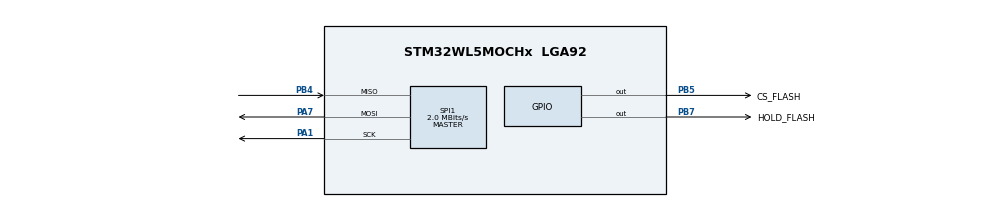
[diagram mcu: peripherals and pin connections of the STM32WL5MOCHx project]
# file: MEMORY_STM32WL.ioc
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Mcu.Family=STM32WL
Mcu.Name=STM32WL5MOCHx
Mcu.Package=LGA92
NVIC.PriorityGroup=NVIC_PRIORITYGROUP_4
PA1.Mode=Full_Duplex_Master
PA1.Signal=SPI1_SCK
PA7.Mode=Full_Duplex_Master
PA7.Signal=SPI1_MOSI
PB4.Mode=Full_Duplex_Master
PB4.Signal=SPI1_MISO
PB5.GPIO_Label=CS_FLASH
PB5.PinState=GPIO_PIN_SET
PB5.Signal=GPIO_Output
PB7.GPIO_Label=HOLD_FLASH
PB7.PinState=GPIO_PIN_SET
PB7.Signal=GPIO_Output
ProjectManager.HeapSize=0x200
ProjectManager.StackSize=0x400
ProjectManager.TargetToolchain=STM32CubeIDE
RCC.HSE_VALUE=32000000
RCC.HSI_VALUE=16000000
RCC.LSE_VALUE=32768
RCC.VCOOutputFreq_Value=32000000
SPI1.CalculateBaudRate=2.0 MBits/s
SPI1.DataSize=SPI_DATASIZE_8BIT
SPI1.Direction=SPI_DIRECTION_2LINES
SPI1.Mode=SPI_MODE_MASTER
SPI1.NSSPMode=SPI_NSS_PULSE_DISABLE
SPI1.VirtualType=VM_MASTER
board=custom

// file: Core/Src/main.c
/* USER CODE BEGIN Header */
/**
 ******************************************************************************
 * @file           : main.c
 * @brief          : Main program body
 ******************************************************************************
 * @attention
 *
 * Copyright (c) 2026 STMicroelectronics.
 * All rights reserved.
 *
 * This software is licensed under terms that can be found in the LICENSE file
 * in the root directory of this software component.
 * If no LICENSE file comes with this software, it is provided AS-IS.
 *
 ******************************************************************************
 */
/* USER CODE END Header */
#include "main.h"

/* USER CODE BEGIN Includes */
#include "MX25L4x/MX25L4x.h"

/* USER CODE END Includes */

SPI_HandleTypeDef hspi1;

/* USER CODE BEGIN PV */
uint32_t memID;
uint8_t pData[50];
/* USER CODE END PV */

void SystemClock_Config(void);
static void MX_GPIO_Init(void);
static void MX_SPI1_Init(void);

int main(void)
{

	/* MCU Configuration--------------------------------------------------------*/

	/* Reset of all peripherals, Initializes the Flash interface and the Systick. */
	HAL_Init();

	/* Configure the system clock */
	SystemClock_Config();

	/* Initialize all configured peripherals */
	MX_GPIO_Init();
	MX_SPI1_Init();
	/* USER CODE BEGIN 2 */

	MX25L4_Init();

	/* USER CODE END 2 */

	/* Infinite loop */
	while (1)
	{

	}
}

void SystemClock_Config(void)
{
	RCC_OscInitTypeDef RCC_OscInitStruct =
	{ 0 };
	RCC_ClkInitTypeDef RCC_ClkInitStruct =
	{ 0 };

	/** Configure the main internal regulator output voltage
	 */
	__HAL_PWR_VOLTAGESCALING_CONFIG(PWR_REGULATOR_VOLTAGE_SCALE2);

	/** Initializes the CPU, AHB and APB buses clocks
	 */
	RCC_OscInitStruct.OscillatorType = RCC_OSCILLATORTYPE_MSI;
	RCC_OscInitStruct.MSIState = RCC_MSI_ON;
	RCC_OscInitStruct.MSICalibrationValue = RCC_MSICALIBRATION_DEFAULT;
	RCC_OscInitStruct.MSIClockRange = RCC_MSIRANGE_6;
	RCC_OscInitStruct.PLL.PLLState = RCC_PLL_NONE;
	if (HAL_RCC_OscConfig(&RCC_OscInitStruct) != HAL_OK)
	{
		Error_Handler();
	}

	/** Configure the SYSCLKSource, HCLK, PCLK1 and PCLK2 clocks dividers
	 */
	RCC_ClkInitStruct.ClockType = RCC_CLOCKTYPE_HCLK3 | RCC_CLOCKTYPE_HCLK | RCC_CLOCKTYPE_SYSCLK | RCC_CLOCKTYPE_PCLK1
			| RCC_CLOCKTYPE_PCLK2;
	RCC_ClkInitStruct.SYSCLKSource = RCC_SYSCLKSOURCE_MSI;
	RCC_ClkInitStruct.AHBCLKDivider = RCC_SYSCLK_DIV1;
	RCC_ClkInitStruct.APB1CLKDivider = RCC_HCLK_DIV1;
	RCC_ClkInitStruct.APB2CLKDivider = RCC_HCLK_DIV1;
	RCC_ClkInitStruct.AHBCLK3Divider = RCC_SYSCLK_DIV1;

	if (HAL_RCC_ClockConfig(&RCC_ClkInitStruct, FLASH_LATENCY_0) != HAL_OK)
	{
		Error_Handler();
	}
}

static void MX_SPI1_Init(void)
{

	/* SPI1 parameter configuration*/
	hspi1.Instance = SPI1;
	hspi1.Init.Mode = SPI_MODE_MASTER;
	hspi1.Init.Direction = SPI_DIRECTION_2LINES;
	hspi1.Init.DataSize = SPI_DATASIZE_8BIT;
	hspi1.Init.CLKPolarity = SPI_POLARITY_LOW;
	hspi1.Init.CLKPhase = SPI_PHASE_1EDGE;
	hspi1.Init.NSS = SPI_NSS_SOFT;
	hspi1.Init.BaudRatePrescaler = SPI_BAUDRATEPRESCALER_2;
	hspi1.Init.FirstBit = SPI_FIRSTBIT_MSB;
	hspi1.Init.TIMode = SPI_TIMODE_DISABLE;
	hspi1.Init.CRCCalculation = SPI_CRCCALCULATION_DISABLE;
	hspi1.Init.CRCPolynomial = 7;
	hspi1.Init.CRCLength = SPI_CRC_LENGTH_DATASIZE;
	hspi1.Init.NSSPMode = SPI_NSS_PULSE_DISABLE;
	if (HAL_SPI_Init(&hspi1) != HAL_OK)
	{
		Error_Handler();
	}

}

static void MX_GPIO_Init(void)
{
	GPIO_InitTypeDef GPIO_InitStruct =
	{ 0 };

	/* GPIO Ports Clock Enable */
	__HAL_RCC_GPIOA_CLK_ENABLE();
	__HAL_RCC_GPIOB_CLK_ENABLE();

	/*Configure GPIO pin Output Level */
	HAL_GPIO_WritePin(GPIOB, HOLD_FLASH_Pin | CS_FLASH_Pin, GPIO_PIN_SET);

	/*Configure GPIO pins : HOLD_FLASH_Pin CS_FLASH_Pin */
	GPIO_InitStruct.Pin = HOLD_FLASH_Pin | CS_FLASH_Pin;
	GPIO_InitStruct.Mode = GPIO_MODE_OUTPUT_PP;
	GPIO_InitStruct.Pull = GPIO_NOPULL;
	GPIO_InitStruct.Speed = GPIO_SPEED_FREQ_LOW;
	HAL_GPIO_Init(GPIOB, &GPIO_InitStruct);

}

void Error_Handler(void)
{
	__disable_irq();
	while (1)
	{
	}
}
